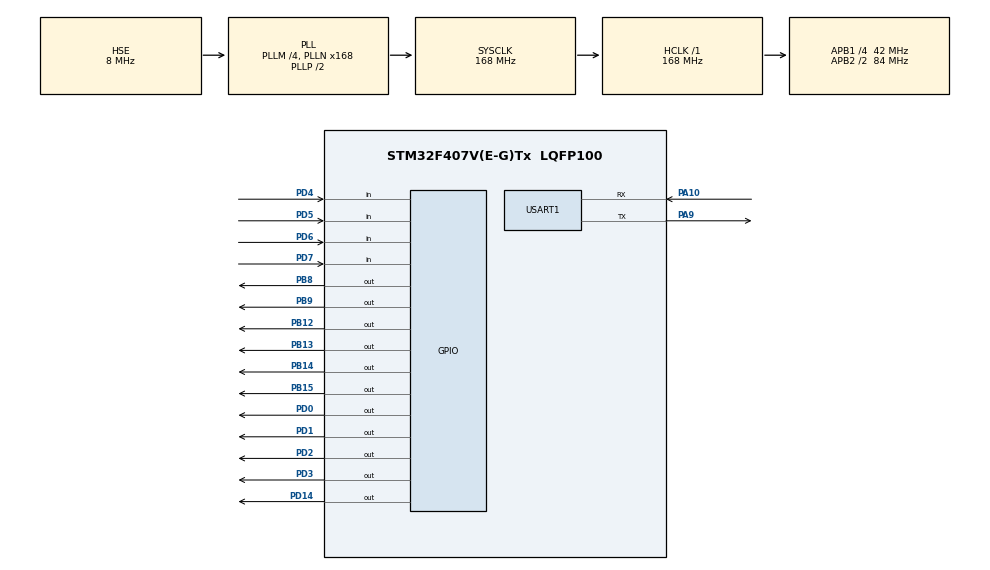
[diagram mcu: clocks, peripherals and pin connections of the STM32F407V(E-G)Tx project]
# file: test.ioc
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Mcu.Family=STM32F4
Mcu.Name=STM32F407V(E-G)Tx
Mcu.Package=LQFP100
NVIC.PriorityGroup=NVIC_PRIORITYGROUP_4
NVIC.TIM2_IRQn=true\:0\:0\:false\:false\:true\:true\:true\:true
NVIC.TIM3_IRQn=true\:0\:0\:false\:false\:true\:true\:true\:true
NVIC.USART1_IRQn=true\:0\:0\:false\:false\:true\:true\:true\:true
PA10.Mode=Asynchronous
PA10.Signal=USART1_RX
PA13.Mode=Serial_Wire
PA13.Signal=SYS_JTMS-SWDIO
PA14.Mode=Serial_Wire
PA14.Signal=SYS_JTCK-SWCLK
PA9.Mode=Asynchronous
PA9.Signal=USART1_TX
PB12.GPIO_Speed=GPIO_SPEED_FREQ_MEDIUM
PB12.Signal=GPIO_Output
PB13.GPIO_Speed=GPIO_SPEED_FREQ_MEDIUM
PB13.Signal=GPIO_Output
PB14.GPIO_Speed=GPIO_SPEED_FREQ_MEDIUM
PB14.Signal=GPIO_Output
PB15.GPIO_Speed=GPIO_SPEED_FREQ_MEDIUM
PB15.Signal=GPIO_Output
PB8.GPIO_ModeDefaultOutputPP=GPIO_MODE_OUTPUT_OD
PB8.GPIO_PuPd=GPIO_NOPULL
PB8.GPIO_Speed=GPIO_SPEED_FREQ_HIGH
PB8.Signal=GPIO_Output
PB9.GPIO_ModeDefaultOutputPP=GPIO_MODE_OUTPUT_OD
PB9.GPIO_PuPd=GPIO_NOPULL
PB9.GPIO_Speed=GPIO_SPEED_FREQ_HIGH
PB9.Signal=GPIO_Output
PD0.GPIO_Speed=GPIO_SPEED_FREQ_MEDIUM
PD0.Signal=GPIO_Output
PD1.GPIO_Speed=GPIO_SPEED_FREQ_MEDIUM
PD1.Signal=GPIO_Output
PD14.Signal=GPIO_Output
PD2.GPIO_Speed=GPIO_SPEED_FREQ_MEDIUM
PD2.Signal=GPIO_Output
PD3.GPIO_Speed=GPIO_SPEED_FREQ_MEDIUM
PD3.Signal=GPIO_Output
PD4.GPIO_PuPd=GPIO_PULLUP
PD4.Signal=GPIO_Input
PD5.GPIO_PuPd=GPIO_PULLUP
PD5.Signal=GPIO_Input
PD6.GPIO_PuPd=GPIO_PULLUP
PD6.Signal=GPIO_Input
PD7.GPIO_PuPd=GPIO_PULLUP
PD7.Signal=GPIO_Input
PH0-OSC_IN.Mode=HSE-External-Oscillator
PH0-OSC_IN.Signal=RCC_OSC_IN
PH1-OSC_OUT.Mode=HSE-External-Oscillator
PH1-OSC_OUT.Signal=RCC_OSC_OUT
ProjectManager.HeapSize=0x200
ProjectManager.StackSize=0x400
ProjectManager.TargetToolchain=MDK-ARM V5.32
RCC.48MHZClocksFreq_Value=84000000
RCC.AHBFreq_Value=168000000
RCC.APB1CLKDivider=RCC_HCLK_DIV4
RCC.APB1Freq_Value=42000000
RCC.APB1TimFreq_Value=84000000
RCC.APB2CLKDivider=RCC_HCLK_DIV2
RCC.APB2Freq_Value=84000000
RCC.APB2TimFreq_Value=168000000
RCC.CortexFreq_Value=168000000
RCC.HCLKFreq_Value=168000000
RCC.HSE_VALUE=8000000
RCC.HSI_VALUE=16000000
RCC.LSE_VALUE=32768
RCC.PLLM=4
RCC.PLLN=168
RCC.PLLSourceVirtual=RCC_PLLSOURCE_HSE
RCC.SYSCLKFreq_VALUE=168000000
RCC.SYSCLKSource=RCC_SYSCLKSOURCE_PLLCLK
RCC.VCOOutputFreq_Value=336000000
TIM2.AutoReloadPreload=TIM_AUTORELOAD_PRELOAD_DISABLE
TIM2.ClockDivision=TIM_CLOCKDIVISION_DIV1
TIM2.Period=20000-1
TIM2.Prescaler=8400-1
USART1.VirtualMode=VM_ASYNC
VP_TIM2_VS_ClockSourceINT.Mode=Internal
VP_TIM3_VS_ClockSourceINT.Mode=Internal
board=custom

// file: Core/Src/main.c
/* USER CODE BEGIN Header */
/**
  ******************************************************************************
  * @file           : main.c
  * @brief          : Main program body
  ******************************************************************************
  * @attention
  *
  * Copyright (c) 2026 STMicroelectronics.
  * All rights reserved.
  *
  * This software is licensed under terms that can be found in the LICENSE file
  * in the root directory of this software component.
  * If no LICENSE file comes with this software, it is provided AS-IS.
  *
  ******************************************************************************
  */
/* USER CODE END Header */
#include "main.h"
#include "tim.h"
#include "usart.h"
#include "gpio.h"

/* USER CODE BEGIN Includes */
#include "TaskDriver.h"
#include "OLED.h"
#include "Matrix.h"
/* USER CODE END Includes */

void SystemClock_Config(void);

int main(void)
{

  /* MCU Configuration--------------------------------------------------------*/

  /* Reset of all peripherals, Initializes the Flash interface and the Systick. */
  HAL_Init();

  /* Configure the system clock */
  SystemClock_Config();

  /* Initialize all configured peripherals */
  MX_GPIO_Init();
  MX_TIM3_Init();
  MX_USART1_UART_Init();
  MX_TIM2_Init();
//	OLED_Init();
//	OLED_ShowString(1, 1, "Nahida");
  /* USER CODE BEGIN 2 */

	TaskDriver_Init();
  /* USER CODE END 2 */

  /* Infinite loop */
  /* USER CODE BEGIN WHILE */
  while (1)
  {
//		HAL_GPIO_WritePin(GPIOB, GPIO_PIN_8, 1);
//		HAL_Delay(200);
//		HAL_GPIO_WritePin(GPIOB, GPIO_PIN_8, 0);
//		HAL_Delay(200);
		TaskDriver_Run();
//		uint8_t Key = Matrix_GetNum();
//		OLED_ShowNum(1, 1, Key, 2);
//		HAL_Delay(1500);
    /* USER CODE END WHILE */

  }
}

void SystemClock_Config(void)
{
  RCC_OscInitTypeDef RCC_OscInitStruct = {0};
  RCC_ClkInitTypeDef RCC_ClkInitStruct = {0};

  /** Configure the main internal regulator output voltage
  */
  __HAL_RCC_PWR_CLK_ENABLE();
  __HAL_PWR_VOLTAGESCALING_CONFIG(PWR_REGULATOR_VOLTAGE_SCALE1);

  /** Initializes the RCC Oscillators according to the specified parameters
  * in the RCC_OscInitTypeDef structure.
  */
  RCC_OscInitStruct.OscillatorType = RCC_OSCILLATORTYPE_HSE;
  RCC_OscInitStruct.HSEState = RCC_HSE_ON;
  RCC_OscInitStruct.PLL.PLLState = RCC_PLL_ON;
  RCC_OscInitStruct.PLL.PLLSource = RCC_PLLSOURCE_HSE;
  RCC_OscInitStruct.PLL.PLLM = 4;
  RCC_OscInitStruct.PLL.PLLN = 168;
  RCC_OscInitStruct.PLL.PLLP = RCC_PLLP_DIV2;
  RCC_OscInitStruct.PLL.PLLQ = 4;
  if (HAL_RCC_OscConfig(&RCC_OscInitStruct) != HAL_OK)
  {
    Error_Handler();
  }

  /** Initializes the CPU, AHB and APB buses clocks
  */
  RCC_ClkInitStruct.ClockType = RCC_CLOCKTYPE_HCLK|RCC_CLOCKTYPE_SYSCLK
                              |RCC_CLOCKTYPE_PCLK1|RCC_CLOCKTYPE_PCLK2;
  RCC_ClkInitStruct.SYSCLKSource = RCC_SYSCLKSOURCE_PLLCLK;
  RCC_ClkInitStruct.AHBCLKDivider = RCC_SYSCLK_DIV1;
  RCC_ClkInitStruct.APB1CLKDivider = RCC_HCLK_DIV4;
  RCC_ClkInitStruct.APB2CLKDivider = RCC_HCLK_DIV2;

  if (HAL_RCC_ClockConfig(&RCC_ClkInitStruct, FLASH_LATENCY_5) != HAL_OK)
  {
    Error_Handler();
  }
}

void Error_Handler(void)
{
  __disable_irq();
  while (1)
  {
  }
}
